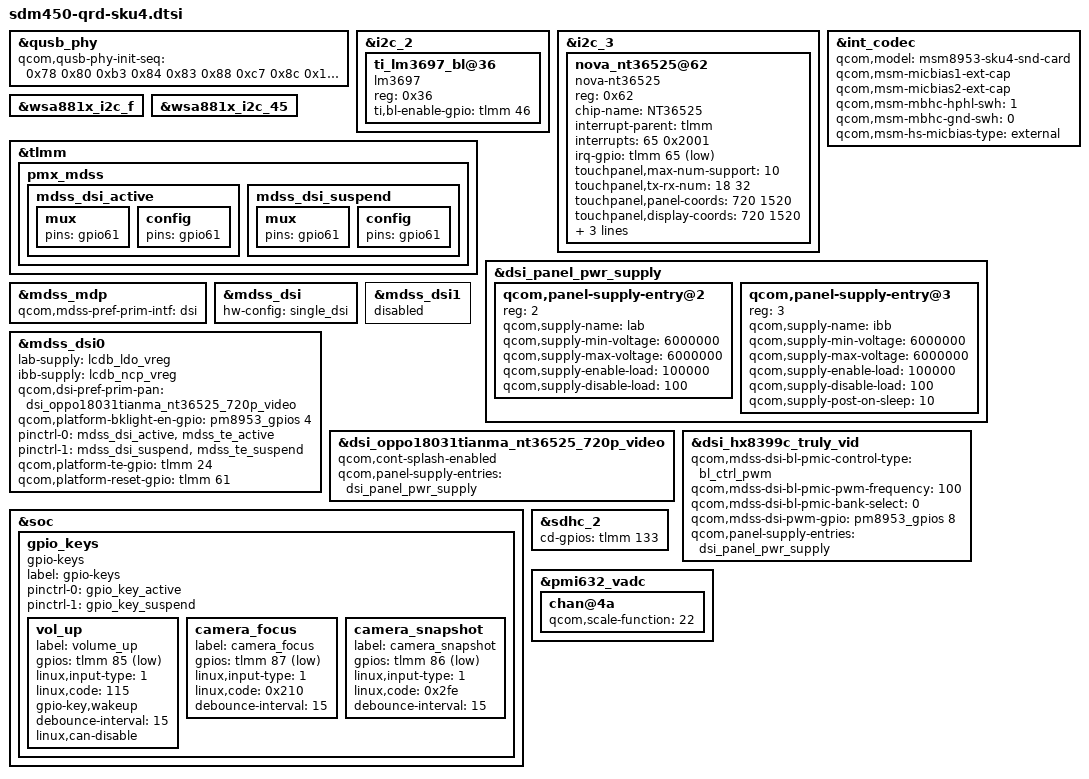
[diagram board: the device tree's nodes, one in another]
/*
 * Copyright (c) 2018, The Linux Foundation. All rights reserved.
 *
 * This program is free software; you can redistribute it and/or modify
 * it under the terms of the GNU General Public License version 2 and
 * only version 2 as published by the Free Software Foundation.
 *
 * This program is distributed in the hope that it will be useful,
 * but WITHOUT ANY WARRANTY; without even the implied warranty of
 * MERCHANTABILITY or FITNESS FOR A PARTICULAR PURPOSE.  See the
 * GNU General Public License for more details.
 */

#include "msm8953-qrd.dtsi"
#include "msm8953-mdss-panels.dtsi"
#include "msm8953-camera-sensor-qrd.dtsi"

&qusb_phy {
	qcom,qusb-phy-init-seq = <0x78 0x80
				0xb3 0x84
				0x83 0x88
				0xc7 0x8c
				0x14 0x9c
				0x30 0x08
				0x79 0x0c
				0x21 0x10
				0x00 0x90
				0x9f 0x1c
				0x00 0x18>;
};

&i2c_2 {
    //ifdef VENDOR_EDIT
    //shengjun.gou@SWDP.MultiMedia, 2016/09/14  Add for 16027 Lcd backlight i2c
    ti_lm3697_bl@36 {
            compatible = "lm3697";
            reg = <0x36>;
            ti,bl-enable-gpio = <&tlmm 46 0x00>;
    };
    //#endif VENDOR_EDIT
};

&i2c_3 {
    //#ifdef VENDOR_EDIT
	//MingQiang.Guo@BSP.group 2018-04-07 add for enable i2c_3 for tp
	status = "okay";
	nova_nt36525@62 {
		compatible = "nova-nt36525";
		reg = <0x62>;
		status = "okay";
		chip-name = "NT36525";

		interrupt-parent = <&tlmm>;
		interrupts = <65 0x2001>;
		irq-gpio = <&tlmm 65 0x2001>;

		pinctrl-names = "default";
		//pinctrl-0 = <&tp_irq_pin_default &tp_rst_pin_default>;

		touchpanel,max-num-support = <10>;
		touchpanel,tx-rx-num = <18 32>;
		touchpanel,panel-coords = <720 1520>;
		touchpanel,display-coords = <720 1520>;

		incell_screen;
		//edge_limit_support;
		//black_gesture_support;
		//charger_pump_support;
		//esd_handle_support;
		//spurious_fingerprint_support;
		//lcd_trigger_fp_check;
		black_gesture_test_support;

		/*
		*Virtual Key Config:
		*1:touchpanel,button-type: <virtualkey_type  supportted_button-map>
		*virtualkey_type:
		*Type 1: using board_properties
		*Type 2: using same IC (button zone&& touch zone are seprate)
		*Type 3: using diffrent IC (button zone&& touch zone are seprate)
		*Type 4: No need of virtual key process
		*supportted_button-map:select|menu|home|back
		*
		*2:touchpanel,button-map
		*type (X1,Y1)(X2,Y2)(X3,Y3)(Width_X,Hight_Y)--Only when button-type is 0
		*/

		touchpanel,button-type = <2 0x05>;
	};
    //#endif VENDOR_EDIT	
};

&int_codec {
	status = "okay";
	qcom,model = "msm8953-sku4-snd-card";
	qcom,msm-micbias1-ext-cap;
	qcom,msm-micbias2-ext-cap;
	qcom,msm-mbhc-hphl-swh = <1>;
	qcom,msm-mbhc-gnd-swh = <0>;
	qcom,msm-hs-micbias-type = "external";
};

&wsa881x_i2c_f {
	status = "okay";
};

&wsa881x_i2c_45 {
	status = "okay";
};

&tlmm {
	pmx_mdss {
		mdss_dsi_active: mdss_dsi_active {
			mux {
				pins = "gpio61";
			};
			config {
				pins = "gpio61";
			};
		};
		mdss_dsi_suspend: mdss_dsi_suspend {
			mux {
				pins = "gpio61";
			};
			config {
				pins = "gpio61";
			};
		};
	};
};

&dsi_panel_pwr_supply {
	qcom,panel-supply-entry@2 {
		reg = <2>;
		qcom,supply-name = "lab";
		qcom,supply-min-voltage = <6000000>;
		qcom,supply-max-voltage = <6000000>;
		qcom,supply-enable-load = <100000>;
		qcom,supply-disable-load = <100>;
	};

	qcom,panel-supply-entry@3 {
		reg = <3>;
		qcom,supply-name = "ibb";
		qcom,supply-min-voltage = <6000000>;
		qcom,supply-max-voltage = <6000000>;
		qcom,supply-enable-load = <100000>;
		qcom,supply-disable-load = <100>;
		qcom,supply-post-on-sleep = <10>;
	};
};

&mdss_mdp {
	qcom,mdss-pref-prim-intf = "dsi";
};

&mdss_dsi {
	hw-config = "single_dsi";
};

&mdss_dsi0 {
	lab-supply = <&lcdb_ldo_vreg>;
	ibb-supply = <&lcdb_ncp_vreg>;
	/delete-property/ vdd-supply;

	qcom,dsi-pref-prim-pan = <&dsi_oppo18031tianma_nt36525_720p_video>;
	qcom,platform-bklight-en-gpio = <&pm8953_gpios 4 0>;
	pinctrl-names = "mdss_default", "mdss_sleep";
	pinctrl-0 = <&mdss_dsi_active &mdss_te_active>;
	pinctrl-1 = <&mdss_dsi_suspend &mdss_te_suspend>;
	qcom,platform-te-gpio = <&tlmm 24 0>;
	qcom,platform-reset-gpio = <&tlmm 61 0>;
};

&mdss_dsi1 {
	status = "disabled";
};

&dsi_oppo18031tianma_nt36525_720p_video {
	qcom,cont-splash-enabled;
	qcom,panel-supply-entries = <&dsi_panel_pwr_supply>;
};
&dsi_hx8399c_truly_vid {
	qcom,mdss-dsi-bl-pmic-control-type = "bl_ctrl_pwm";
	qcom,mdss-dsi-bl-pmic-pwm-frequency = <100>;
	qcom,mdss-dsi-bl-pmic-bank-select = <0>;
	qcom,mdss-dsi-pwm-gpio = <&pm8953_gpios 8 0>;
	qcom,panel-supply-entries = <&dsi_panel_pwr_supply>;
};

&soc {
	gpio_keys {
		compatible = "gpio-keys";
		label = "gpio-keys";
		pinctrl-names = "default", "sleep";
		pinctrl-0 = <&gpio_key_active>;
		pinctrl-1 = <&gpio_key_suspend>;

		vol_up {
			label = "volume_up";
			gpios = <&tlmm 85 GPIO_ACTIVE_LOW>;
			linux,input-type = <1>;
			linux,code = <115>;
			gpio-key,wakeup;
			debounce-interval = <15>;
			linux,can-disable;
		};
	};
};

&sdhc_2 {
	cd-gpios = <&tlmm 133 0x0>;
};

&pmi632_vadc {
	chan@4a {
		qcom,scale-function = <22>;
	};
};

&soc {
	gpio_keys {
		camera_focus {
			label = "camera_focus";
			gpios = <&tlmm 87 0x1>;
			linux,input-type = <1>;
			linux,code = <0x210>;
			debounce-interval = <15>;
		};

		camera_snapshot {
			label = "camera_snapshot";
			gpios = <&tlmm 86 0x1>;
			linux,input-type = <1>;
			linux,code = <0x2fe>;
			debounce-interval = <15>;
		};
	};
};

